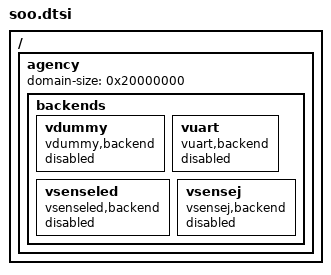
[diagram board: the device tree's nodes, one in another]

/ {

	agency: agency {
	
		domain-size = <0x20000000>; /* 512 MB */	
				
		/* Backends */

		backends {

			vdummy {
				compatible = "vdummy,backend";
				status = "disabled";
			};
	
			vuart {
				compatible = "vuart,backend";
				status = "disabled";
			};
			
			vsenseled {
            	compatible = "vsenseled,backend";
            	status = "disabled";
        	};
			
        	vsensej {
            	compatible = "vsensej,backend";
            	status = "disabled";
        	};
			
		};
	};
	
};
